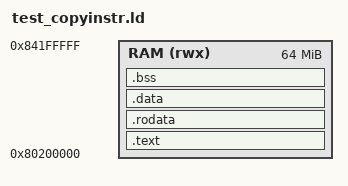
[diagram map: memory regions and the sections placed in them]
OUTPUT_ARCH(riscv)
ENTRY(_start)

MEMORY
{
    RAM (rwx) : ORIGIN = 0x80200000, LENGTH = 64M
}

SECTIONS
{
    .text : {
        *(.text._start)
        *(.text)
        *(.text.*)
    } > RAM

    .rodata : {
        *(.rodata)
        *(.rodata.*)
    } > RAM

    .data : {
        *(.data)
        *(.data.*)
        *(.sdata)
        *(.sdata.*)
    } > RAM

    .bss : {
        __bss_start = .;
        *(.bss)
        *(.bss.*)
        *(.sbss)
        *(.sbss.*)
        *(COMMON)
        __bss_end = .;
    } > RAM

    /DISCARD/ : {
        *(.riscv.attributes)
    }
}
